# bao1x_peri register map
Vendor: baochip
Registers are 32-bit, read-write, reset 0x0 unless marked. A register's access mark holds for its fields unless they carry their own. Offsets are from the block's base; [hi:lo] are bit positions; {n}, {i} and the like mark numbered series; <NAME> marks a mode.

## BIO_FIFO1
Base 0x5012A000
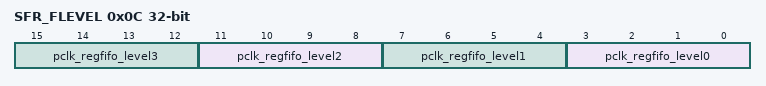
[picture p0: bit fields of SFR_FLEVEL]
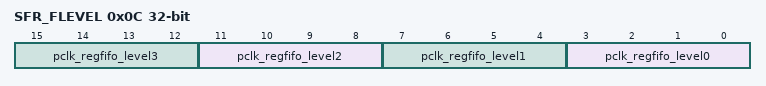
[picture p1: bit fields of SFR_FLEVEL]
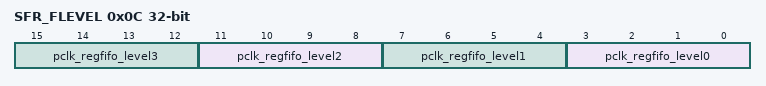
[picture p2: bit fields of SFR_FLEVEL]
0x0C SFR_FLEVEL — See `bio_bdma.sv#L492 <https://github.com/baochip/baochip-1x/blob/main/rtl/modul es/bio_bdma/rtl/bio_bdma.sv#L492>`__ (line numbers are approximate)
  [4n+3:4n] pclk_regfifo_level{n} (n=0..3) — pclk_regfifo_level[{n}] read only status register
0x14 SFR_TXF1 — See `bio_bdma.sv#L494 <https://github.com/baochip/baochip-1x/blob/main/rtl/modul es/bio_bdma/rtl/bio_bdma.sv#L494>`__ (line numbers are approximate)
  [31:0] fdin — fdin read/write control register
0x24 SFR_RXF1 — See `bio_bdma.sv#L498 <https://github.com/baochip/baochip-1x/blob/main/rtl/modul es/bio_bdma/rtl/bio_bdma.sv#L498>`__ (line numbers are approximate)
  [31:0] fdout — fdout read only status register
0x38 SFR_EVENT_SET — See `bio_bdma.sv#L504 <https://github.com/baochip/baochip-1x/blob/main/rtl/modul es/bio_bdma/rtl/bio_bdma.sv#L504>`__ (line numbers are approximate)
  [23:0] sfr_event_set — sfr_event_set read/write control register
0x3C SFR_EVENT_CLR — See `bio_bdma.sv#L505 <https://github.com/baochip/baochip-1x/blob/main/rtl/modul es/bio_bdma/rtl/bio_bdma.sv#L505>`__ (line numbers are approximate)
  [23:0] sfr_event_clr — sfr_event_clr read/write control register
0x40 SFR_EVENT_STATUS — See `bio_bdma.sv#L506 <https://github.com/baochip/baochip-1x/blob/main/rtl/modul es/bio_bdma/rtl/bio_bdma.sv#L506>`__ (line numbers are approximate)
  [31:0] sfr_event_status — sfr_event_status read only status register

## BIO_FIFO2
Base 0x5012B000
0x0C SFR_FLEVEL — See `bio_bdma.sv#L492 <https://github.com/baochip/baochip-1x/blob/main/rtl/modul es/bio_bdma/rtl/bio_bdma.sv#L492>`__ (line numbers are approximate)
  [4n+3:4n] pclk_regfifo_level{n} (n=0..3) — pclk_regfifo_level[{n}] read only status register
0x18 SFR_TXF2 — See `bio_bdma.sv#L495 <https://github.com/baochip/baochip-1x/blob/main/rtl/modul es/bio_bdma/rtl/bio_bdma.sv#L495>`__ (line numbers are approximate)
  [31:0] fdin — fdin read/write control register
0x28 SFR_RXF2 — See `bio_bdma.sv#L499 <https://github.com/baochip/baochip-1x/blob/main/rtl/modul es/bio_bdma/rtl/bio_bdma.sv#L499>`__ (line numbers are approximate)
  [31:0] fdout — fdout read only status register
0x38 SFR_EVENT_SET — See `bio_bdma.sv#L504 <https://github.com/baochip/baochip-1x/blob/main/rtl/modul es/bio_bdma/rtl/bio_bdma.sv#L504>`__ (line numbers are approximate)
  [23:0] sfr_event_set — sfr_event_set read/write control register
0x3C SFR_EVENT_CLR — See `bio_bdma.sv#L505 <https://github.com/baochip/baochip-1x/blob/main/rtl/modul es/bio_bdma/rtl/bio_bdma.sv#L505>`__ (line numbers are approximate)
  [23:0] sfr_event_clr — sfr_event_clr read/write control register
0x40 SFR_EVENT_STATUS — See `bio_bdma.sv#L506 <https://github.com/baochip/baochip-1x/blob/main/rtl/modul es/bio_bdma/rtl/bio_bdma.sv#L506>`__ (line numbers are approximate)
  [31:0] sfr_event_status — sfr_event_status read only status register

## BIO_FIFO3
Base 0x5012C000
0x0C SFR_FLEVEL — See `bio_bdma.sv#L492 <https://github.com/baochip/baochip-1x/blob/main/rtl/modul es/bio_bdma/rtl/bio_bdma.sv#L492>`__ (line numbers are approximate)
  [4n+3:4n] pclk_regfifo_level{n} (n=0..3) — pclk_regfifo_level[{n}] read only status register
0x1C SFR_TXF3 — See `bio_bdma.sv#L496 <https://github.com/baochip/baochip-1x/blob/main/rtl/modul es/bio_bdma/rtl/bio_bdma.sv#L496>`__ (line numbers are approximate)
  [31:0] fdin — fdin read/write control register
0x2C SFR_RXF3 — See `bio_bdma.sv#L500 <https://github.com/baochip/baochip-1x/blob/main/rtl/modul es/bio_bdma/rtl/bio_bdma.sv#L500>`__ (line numbers are approximate)
  [31:0] fdout — fdout read only status register
0x38 SFR_EVENT_SET — See `bio_bdma.sv#L504 <https://github.com/baochip/baochip-1x/blob/main/rtl/modul es/bio_bdma/rtl/bio_bdma.sv#L504>`__ (line numbers are approximate)
  [23:0] sfr_event_set — sfr_event_set read/write control register
0x3C SFR_EVENT_CLR — See `bio_bdma.sv#L505 <https://github.com/baochip/baochip-1x/blob/main/rtl/modul es/bio_bdma/rtl/bio_bdma.sv#L505>`__ (line numbers are approximate)
  [23:0] sfr_event_clr — sfr_event_clr read/write control register
0x40 SFR_EVENT_STATUS — See `bio_bdma.sv#L506 <https://github.com/baochip/baochip-1x/blob/main/rtl/modul es/bio_bdma/rtl/bio_bdma.sv#L506>`__ (line numbers are approximate)
  [31:0] sfr_event_status — sfr_event_status read only status register
